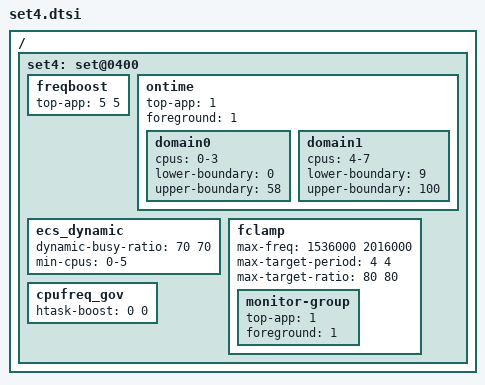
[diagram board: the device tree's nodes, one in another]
/ {
	/* balance mode - default */
	set4: set@0400 {
		/* Boosting margin applied to frequency selection */
		freqboost {			/* LIT BIG */
			top-app			= <  5   5>;
		};

		/* Ontime Migration */
		ontime {
			top-app		= <1>;
			foreground	= <1>;

			domain0 {
				cpus = "0-3";
				lower-boundary = <0>;
				upper-boundary = <58>;
			};
			domain1 {
				cpus = "4-7";
				lower-boundary = <9>;
				upper-boundary = <100>;
			};
		};

		ecs_dynamic {
			dynamic-busy-ratio	= <70 70>;
			min-cpus = "0-5";
		};

		fclamp {
			max-freq          = < 1536000 2016000>;
			max-target-period = <       4       4>;
			max-target-ratio  = <      80      80>;

			monitor-group {
				top-app         = <1>;
				foreground      = <1>;
			};
		};

		cpufreq_gov {
				/* LIT BIG */
			htask-boost = < 0 0 >;
		};
	};
};
